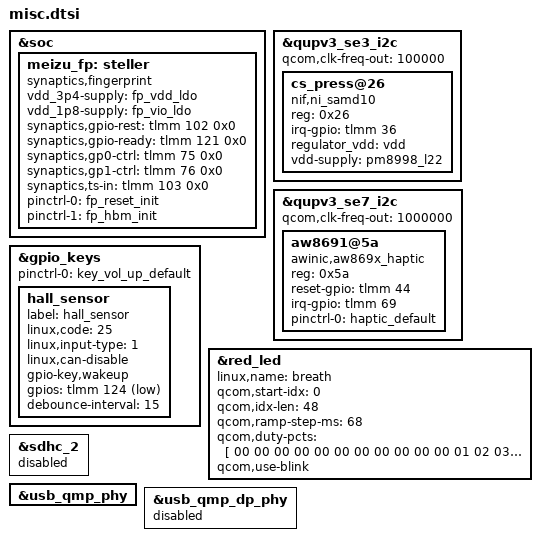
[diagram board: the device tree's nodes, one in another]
/*
 * Copyright (c) 2024, MeizuCustoms enthusiasts
 *
 * This program is free software; you can redistribute it and/or modify
 * it under the terms of the GNU General Public License version 2 and
 * only version 2 as published by the Free Software Foundation.
 *
 * This program is distributed in the hope that it will be useful,
 * but WITHOUT ANY WARRANTY; without even the implied warranty of
 * MERCHANTABILITY or FITNESS FOR A PARTICULAR PURPOSE.  See the
 * GNU General Public License for more details.
 */

&soc {
    meizu_fp: steller {
		status = "okay";
		compatible = "synaptics,fingerprint";
		vdd_3p4-supply = <&fp_vdd_ldo>;
		vdd_1p8-supply = <&fp_vio_ldo>;
		synaptics,gpio-rest = <&tlmm 102 0x0>;
		synaptics,gpio-ready = <&tlmm 121 0x0>;
		synaptics,gp0-ctrl = <&tlmm 75 0x0>;
		synaptics,gp1-ctrl = <&tlmm 76 0x0>;
		synaptics,ts-in = <&tlmm 103 0x0>;
		pinctrl-names = "fp_reset_init", "fp_hbm_init";
		pinctrl-0 = <&fp_reset_init>;
		pinctrl-1 = <&fp_hbm_init>;
	};
};

&qupv3_se3_i2c {
	status = "ok";
	qcom,clk-freq-out = <100000>;

	cs_press@26 {
		compatible = "nif,ni_samd10";
		reg = <0x26>;

		irq-gpio = <&tlmm 36 0x0>;
		regulator_vdd = "vdd";
		vdd-supply = <&pm8998_l22>;

		status = "ok";
	};
};

/* m1882: AWINIC AW8691 haptics; m1892 uses DW7914 on SE12 (see m1892-overlay.dtsi) */
#ifndef MZ_M1892
&qupv3_se7_i2c {
	status = "ok";
	qcom,clk-freq-out = <1000000>;

	aw8691@5a {
		compatible = "awinic,aw869x_haptic";
		reg = <0x5a>;

		reset-gpio = <&tlmm 44 0x0>;
		irq-gpio = <&tlmm 69 0x0>;

		pinctrl-names = "default";
		pinctrl-0 = <&haptic_default>;
	};
};
#endif

&gpio_keys {
	pinctrl-0 = <&key_vol_up_default>;
	/delete-node/ cam_focus;
	/delete-node/ cam_snapshot;

	hall_sensor {
		label = "hall_sensor";
		linux,code = <25>;
		linux,input-type = <1>;
		linux,can-disable;

		gpio-key,wakeup;
		gpios = <&tlmm 124 0x1>;
		debounce-interval = <15>;
	};
};

&red_led {
	linux,name = "breath";

	qcom,start-idx = <0>;
	qcom,idx-len = <48>;
	qcom,ramp-step-ms = <68>;
	qcom,duty-pcts = [
		00 00 00 00 00 00 00 00
		00 00 00 01 02 03 04 05
		06 07 08 09 0a 0b 0c 0d
		0c 0b 0a 09 08 07 06 05
		04 03 02 01 00 00 00 00
		00 00 00 00 00 00 00 00
	];
	
	qcom,use-blink;
};

&sdhc_2 {
	status = "disabled";
	/delete-property/ cd-gpios;
};

&usb_qmp_phy {
	status = "ok";
};

&usb_qmp_dp_phy {
	status = "disabled";
};
